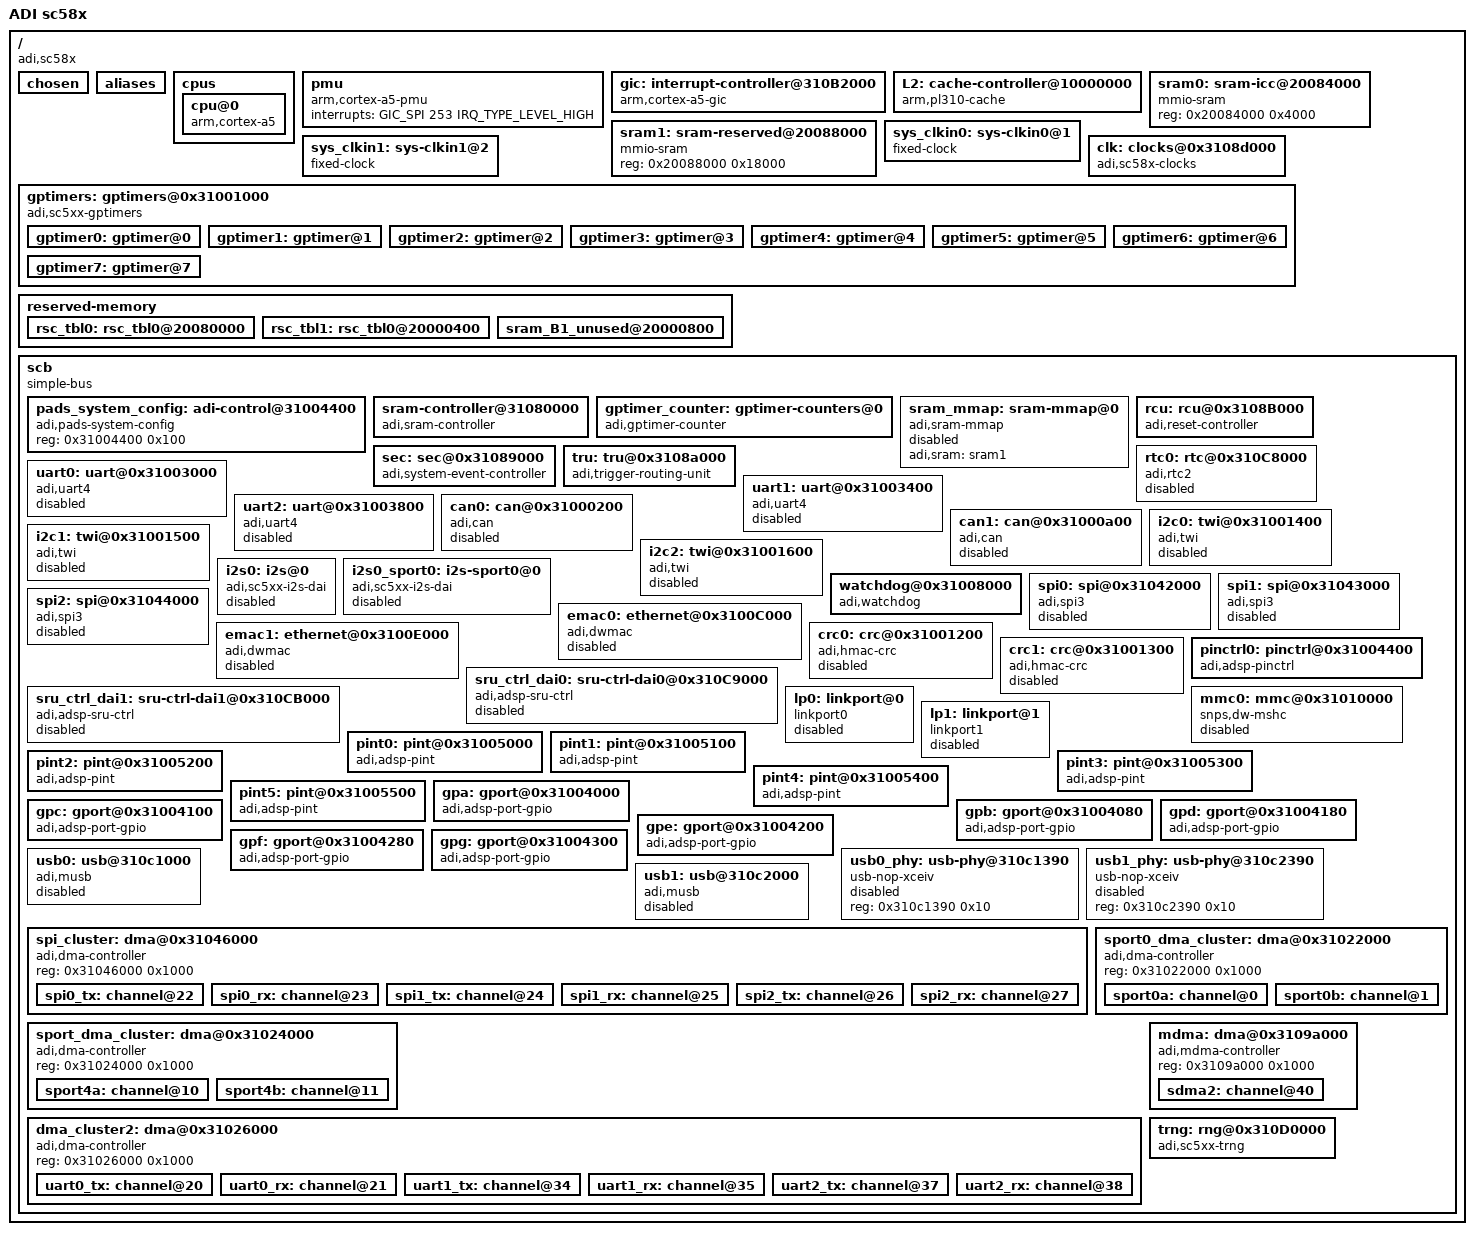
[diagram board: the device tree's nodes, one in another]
/*
 * Device tree header for ADI sc58x processor
 *
 * Copyright 2014 - 2018 Analog Devices Inc.
 *
 * Licensed under the GPL-2 or later.
 *
 */

#include <dt-bindings/interrupt-controller/arm-gic.h>
#include <dt-bindings/interrupt-controller/irq.h>
#include <dt-bindings/clock/adi-sc5xx-clock.h>

/ {
	model = "ADI sc58x";
	compatible = "adi,sc58x";
	interrupt-parent = <&gic>;
	#address-cells = <1>;
	#size-cells = <1>;

	chosen { };

	aliases {
		serial0 = &uart0;
		timer0 = &gptimer0;
		timer1 = &gptimer1;
		timer2 = &gptimer2;
		timer3 = &gptimer3;
		timer4 = &gptimer4;
		timer5 = &gptimer5;
		timer6 = &gptimer6;
		timer7 = &gptimer7;
		ethernet0 = &emac0;
		ethernet1 = &emac1;
		spi0   = &spi0;
		spi1   = &spi1;
		spi2   = &spi2;
		can0 = &can0;
		can1 = &can1;
		i2c0 = &i2c0;
		i2c1 = &i2c1;
		i2c2 = &i2c2;
		rtc0 = &rtc0;
		i2s0 = &i2s0;
		mmc0 = &mmc0;
		sru0 = &sru_ctrl_dai0;
		sru1 = &sru_ctrl_dai1;
	};

	cpus {
		#size-cells = <0>;
		#address-cells = <1>;

		cpu@0 {
			device_type = "cpu";
			compatible = "arm,cortex-a5";
			reg = <0x0>;
			clocks = <&clk ADSP_SC58X_CLK_ARM>;
		};
	};

	pmu {
		compatible = "arm,cortex-a5-pmu";
		interrupts = <GIC_SPI 253 IRQ_TYPE_LEVEL_HIGH>;
	};

	gic: interrupt-controller@310B2000 {
		compatible = "arm,cortex-a5-gic", "arm,cortex-a9-gic";
		#interrupt-cells = <3>;
		#address-cells = <0>;
		interrupt-controller;
		reg = <0x310B2000 0x1000>,
		      <0x310B4000 0x100>;
	};

	L2: cache-controller@10000000 {
		compatible = "arm,pl310-cache";
		reg = <0x10000000 0x1000>;
		cache-level = <2>;
	};

	sram0: sram-icc@20084000 {
		compatible = "mmio-sram";
		#address-cells = <1>;
		#size-cells = <1>;
		reg = <0x20084000 0x4000>;
		ranges = <0 0x20084000 0x4000>; /* 16 KiB */
	};

	sram1: sram-reserved@20088000 {
		compatible = "mmio-sram";
		#address-cells = <1>;
		#size-cells = <1>;
		reg = <0x20088000 0x18000>;
		ranges = <0 0x20088000 0x18000>; /* 96 KiB */
	};

	sys_clkin0: sys-clkin0@1 {
		compatible = "fixed-clock";
		#clock-cells = <0>;
		clock-frequency = <25000000>;
		clock-output-names = "sys_clkin0";
	};

	sys_clkin1: sys-clkin1@2 {
		compatible = "fixed-clock";
		#clock-cells = <0>;
		clock-frequency = <25000000>;
		clock-output-names = "sys_clkin1";
	};

	clk: clocks@0x3108d000 {
		compatible = "adi,sc58x-clocks";
		reg = <0x3108d000 0x1000>,
			<0x3108e000 0x1000>,
			<0x3108f000 0x1000>;
		#clock-cells = <1>;
		clocks = <&sys_clkin0>, <&sys_clkin1>;
		clock-names = "sys_clkin0", "sys_clkin1";
		status = "okay";
	};

	gptimers: gptimers@0x31001000 {
		compatible = "adi,sc5xx-gptimers";
		reg = <0x31001000 0x200>;
		clocks = <&clk ADSP_SC58X_CLK_CGU0_SCLK0>;
		status = "okay";
		#address-cells = <1>;
		#size-cells = <0>;

		gptimer0: gptimer@0 {
			reg = <0>;
			interrupt-parent = <&gic>;
			interrupts = <GIC_SPI 26 IRQ_TYPE_LEVEL_HIGH>;
			adi,offset = <0x60>;
			adi,is-clocksource;
			adi,reset-timer;
		};

		gptimer1: gptimer@1 {
			reg = <1>;
			interrupt-parent = <&gic>;
			interrupts = <GIC_SPI 27 IRQ_TYPE_LEVEL_HIGH>;
			adi,offset = <0x80>;
			adi,is-clockevent;
			adi,reset-timer;
		};

		gptimer2: gptimer@2 {
			reg = <2>;
			interrupt-parent = <&gic>;
			interrupts = <GIC_SPI 28 IRQ_TYPE_LEVEL_HIGH>;
			adi,offset = <0xa0>;
		};

		gptimer3: gptimer@3 {
			reg = <3>;
			interrupt-parent = <&gic>;
			interrupts = <GIC_SPI 29 IRQ_TYPE_LEVEL_HIGH>;
			adi,offset = <0xc0>;
		};

		gptimer4: gptimer@4 {
			reg = <4>;
			interrupt-parent = <&gic>;
			interrupts = <GIC_SPI 72 IRQ_TYPE_LEVEL_HIGH>;
			adi,offset = <0xe0>;
		};

		gptimer5: gptimer@5 {
			reg = <5>;
			interrupt-parent = <&gic>;
			interrupts = <GIC_SPI 73 IRQ_TYPE_LEVEL_HIGH>;
			adi,offset = <0x100>;
		};

		gptimer6: gptimer@6 {
			reg = <6>;
			interrupt-parent = <&gic>;
			interrupts = <GIC_SPI 74 IRQ_TYPE_LEVEL_HIGH>;
			adi,offset = <0x120>;
		};

		gptimer7: gptimer@7 {
			reg = <7>;
			interrupt-parent = <&gic>;
			interrupts = <GIC_SPI 75 IRQ_TYPE_LEVEL_HIGH>;
			adi,offset = <0x140>;
		};
	};

	reserved-memory {
		#address-cells = <1>;
		#size-cells = <1>;
		ranges;

		rsc_tbl0: rsc_tbl0@20080000 {
			reg = <0x20080000 0x400>; /*1KiB*/
			no-map;
		};

		rsc_tbl1: rsc_tbl0@20000400 {
			reg = <0x20080400 0x400>; /*1KiB*/
			no-map;
		};

		sram_B1_unused@20000800 {
			reg = <0x20080800 0x3800>; /* <128 KiB*/
			no-map;
		};
	};

	scb {
		compatible = "simple-bus";
		#address-cells = <1>;
		#size-cells = <1>;
		ranges;

		pads_system_config: adi-control@31004400 {
			compatible = "adi,pads-system-config";
			reg = <0x31004400 0x100>;
			status = "okay";
		};

		sram-controller@31080000 {
			compatible = "adi,sram-controller";
			reg = <0x31080000 0x100>;
			adi,sram = <&sram0>, <&sram1>;
			interrupts = <GIC_SPI 10 IRQ_TYPE_LEVEL_HIGH>;
			status = "okay";
		};

		gptimer_counter: gptimer-counters@0 {
			compatible = "adi,gptimer-counter";
			status = "okay";
		};

		sram_mmap: sram-mmap@0 { /* mmap from sram1 pool*/
			compatible = "adi,sram-mmap";
			adi,sram = <&sram1>;
			status = "disabled";
		};

		rcu: rcu@0x3108B000 {
			compatible = "adi,reset-controller";
			reg = <0x3108B000 0x1000>;
			adi,sharc-min = <1>;
			adi,sharc-max = <2>;
			adi,enable-reboot;
			status = "okay";
		};

		sec: sec@0x31089000 {
			compatible = "adi,system-event-controller";
			reg = <0x31089000 0x1000>;
			adi,rcu = <&rcu>;
			adi,sharc-cores = <2>;
			status = "okay";
		};

		tru: tru@0x3108a000 {
			compatible = "adi,trigger-routing-unit";
			reg = <0x3108a000 0x1000>;
			adi,max-master-id = <139>;
			adi,max-slave-id = <137>;
			status = "okay";
		};

		rtc0: rtc@0x310C8000 {
			compatible = "adi,rtc2";
			reg = <0x310C8000 0x100>;
			interrupts = <GIC_SPI 165 IRQ_TYPE_LEVEL_HIGH>;
			calibration = /bits/ 8 <0>;
			status = "disabled";
		};

		uart0: uart@0x31003000 {
			compatible = "adi,uart4";
			reg = <0x31003000 0x40>;
			dmas = <&dma_cluster2 20>, <&dma_cluster2 21>;
			dma-names = "tx", "rx";
			interrupt-parent = <&gic>;
			interrupt-names = "tx", "rx", "status";
			interrupts = <GIC_SPI 114 IRQ_TYPE_LEVEL_HIGH>,
				     <GIC_SPI 115 IRQ_TYPE_LEVEL_HIGH>,
				     <GIC_SPI 116 IRQ_TYPE_LEVEL_HIGH>;
			clocks = <&clk ADSP_SC58X_CLK_CGU0_SCLK0>;
			clock-names = "sclk0";
			status = "disabled";
		};

		uart1: uart@0x31003400 {
			compatible = "adi,uart4";
			reg = <0x31003400 0x40>;
			dmas = <&dma_cluster2 34>, <&dma_cluster2 35>;
			dma-names = "tx", "rx";
			interrupt-parent = <&gic>;
			interrupt-names = "tx", "rx", "status";
			interrupts = <GIC_SPI 117 IRQ_TYPE_LEVEL_HIGH>,
				     <GIC_SPI 118 IRQ_TYPE_LEVEL_HIGH>,
				     <GIC_SPI 119 IRQ_TYPE_LEVEL_HIGH>;
			clocks = <&clk ADSP_SC58X_CLK_CGU0_SCLK0>;
			clock-names = "sclk0";
			status = "disabled";
		};

		uart2: uart@0x31003800 {
			compatible = "adi,uart4";
			reg = <0x31003800 0x40>;
			dmas = <&dma_cluster2 37>, <&dma_cluster2 38>;
			dma-names = "tx", "rx";
			interrupt-parent = <&gic>;
			interrupt-names = "tx", "rx", "status";
			interrupts = <GIC_SPI 120 IRQ_TYPE_LEVEL_HIGH>,
				     <GIC_SPI 121 IRQ_TYPE_LEVEL_HIGH>,
				     <GIC_SPI 122 IRQ_TYPE_LEVEL_HIGH>;
			clocks = <&clk ADSP_SC58X_CLK_CGU0_SCLK0>;
			clock-names = "sclk0";
			status = "disabled";
		};

		can0: can@0x31000200 {
			compatible = "adi,can";
			reg = <0x31000200 0x5FF>;
			interrupt-parent = <&gic>;
			interrupts = <GIC_SPI 84 IRQ_TYPE_LEVEL_HIGH>,
				     <GIC_SPI 85 IRQ_TYPE_LEVEL_HIGH>,
				     <GIC_SPI 86 IRQ_TYPE_LEVEL_HIGH>;
			status = "disabled";
		};

		can1: can@0x31000a00 {
			compatible = "adi,can";
			reg = <0x31000a00 0x5FF>;
			interrupt-parent = <&gic>;
			interrupts = <GIC_SPI 87 IRQ_TYPE_LEVEL_HIGH>,
				     <GIC_SPI 88 IRQ_TYPE_LEVEL_HIGH>,
				     <GIC_SPI 89 IRQ_TYPE_LEVEL_HIGH>;
			status = "disabled";
		};

		i2c0: twi@0x31001400 {
			#address-cells = <1>;
			#size-cells = <0>;
			compatible = "adi,twi";
			reg = <0x31001400 0xFF>;
			interrupts = <GIC_SPI 123 IRQ_TYPE_LEVEL_HIGH>;
			clock-khz = <100>;
			clocks = <&clk ADSP_SC58X_CLK_CGU0_SCLK0>;
			clock-names = "sclk0";
			status = "disabled";
		};

		i2c1: twi@0x31001500 {
			#address-cells = <1>;
			#size-cells = <0>;
			compatible = "adi,twi";
			reg = <0x31001500 0xFF>;
			interrupts = <GIC_SPI 124 IRQ_TYPE_LEVEL_HIGH>;
			clock-khz = <100>;
			clocks = <&clk ADSP_SC58X_CLK_CGU0_SCLK0>;
			clock-names = "sclk0";
			status = "disabled";
		};

		i2c2: twi@0x31001600 {
			#address-cells = <1>;
			#size-cells = <0>;
			compatible = "adi,twi";
			reg = <0x31001600 0xFF>;
			interrupts = <GIC_SPI 125 IRQ_TYPE_LEVEL_HIGH>;
			clock-khz = <100>;
			clocks = <&clk ADSP_SC58X_CLK_CGU0_SCLK0>;
			clock-names = "sclk0";
			status = "disabled";
		};

		i2s0: i2s@0 {
			compatible = "adi,sc5xx-i2s-dai";
			reg = <0x31002400 0x80>, <0x31002480 0x80>;
			sport-channel = <4>;
			interrupt-names = "tx_status", "rx_status";
			interrupts = <GIC_SPI 61 IRQ_TYPE_LEVEL_HIGH>, <GIC_SPI 63 IRQ_TYPE_LEVEL_HIGH>;
			dmas = <&sport_dma_cluster 10>, <&sport_dma_cluster 11>;
			dma-names = "tx", "rx";
			iram = <&sram1>;
			clocks = <&clk ADSP_SC58X_CLK_CGU0_SCLK1>;
			clock-names = "sclk";
			status = "disabled";
		};

		i2s0_sport0: i2s-sport0@0 {
			compatible = "adi,sc5xx-i2s-dai";
			reg = <0x31002000 0x80>, <0x31002080 0x80>;
			sport-channel = <0>;
			interrupt-names = "tx_status", "rx_status";
			interrupts = <GIC_SPI 53 IRQ_TYPE_LEVEL_HIGH>, <GIC_SPI 55 IRQ_TYPE_LEVEL_HIGH>;
			dmas = <&sport0_dma_cluster 0>, <&sport0_dma_cluster 1>;
			dma-names = "tx", "rx";
			iram = <&sram1>;
			clocks = <&clk ADSP_SC58X_CLK_CGU0_SCLK1>;
			clock-names = "sclk";
			status = "disabled";
		};

		watchdog@0x31008000 {
			compatible = "adi,watchdog";
			reg = <0x31008000 0x10>;
			timeout-sec = <30>;
			clocks = <&clk ADSP_SC58X_CLK_CGU0_SCLK0>;
			clock-names = "adi-watchdog";
		};

		spi0: spi@0x31042000 {
			#address-cells = <1>;
			#size-cells = <0>;
			compatible = "adi,spi3";
			reg = <0x31042000 0xFF>;
			interrupts = <GIC_SPI 109 IRQ_TYPE_LEVEL_HIGH>;
			dmas = <&spi_cluster 22>, <&spi_cluster 23>;
			dma-names = "tx", "rx";
			clocks = <&clk ADSP_SC58X_CLK_CGU0_SCLK1>;
			clock-names = "spi";
			status = "disabled";
		};

		spi1: spi@0x31043000 {
			#address-cells = <1>;
			#size-cells = <0>;
			compatible = "adi,spi3";
			reg = <0x31043000 0xFF>;
			interrupts = <GIC_SPI 113 IRQ_TYPE_LEVEL_HIGH>;
			dmas = <&spi_cluster 24>, <&spi_cluster 25>;
			dma-names = "tx", "rx";
			clocks = <&clk ADSP_SC58X_CLK_CGU0_SCLK0>;
			clock-names = "spi";
			status = "disabled";
		};

		spi2: spi@0x31044000 {
			#address-cells = <1>;
			#size-cells = <0>;
			compatible = "adi,spi3";
			reg = <0x31044000 0xFF>;
			interrupts = <GIC_SPI 71 IRQ_TYPE_LEVEL_HIGH>;
			dmas = <&spi_cluster 26>, <&spi_cluster 27>;
			dma-names = "tx", "rx";
			clocks = <&clk ADSP_SC58X_CLK_CGU0_SCLK0>;
			clock-names = "spi";
			status = "disabled";
		};

		emac0: ethernet@0x3100C000 {
			compatible = "adi,dwmac", "snps,dwmac-3.710", "snps,dwmac";
			reg = <0x3100C000 0x2000>;
			interrupt-parent = <&gic>;
			interrupts = <GIC_SPI 148 IRQ_TYPE_LEVEL_HIGH>;
			interrupt-names = "macirq";
			snps,mixed-burst;
			snps,pbl = <8>;
			snps,force_sf_dma_mode;
			snps,perfect-filter-entries = <32>;
			clocks = <&clk ADSP_SC58X_CLK_GIGE>;
			clock-names = "stmmaceth";
			adi,system-config = <&pads_system_config>;
			status = "disabled";
		};

		emac1: ethernet@0x3100E000 {
			compatible = "adi,dwmac", "snps,dwmac-3.710", "snps,dwmac";
			reg = <0x3100E000 0x2000>;
			interrupt-parent = <&gic>;
			interrupts = <GIC_SPI 149 IRQ_TYPE_LEVEL_HIGH>;
			interrupt-names = "macirq";
			snps,fixed-burst;
			snps,burst_len = <0x4>;	/* BLEN8 */
			snps,pbl = <1>;
			snps,force_thresh_dma_mode;
			clocks = <&clk ADSP_SC58X_CLK_GIGE>;
			clock-names = "stmmaceth";
			status = "disabled";
		};

		crc0: crc@0x31001200 {
			compatible = "adi,hmac-crc";
			reg = <0x31001200 0xFF>;
			interrupts = <GIC_SPI 176 IRQ_TYPE_LEVEL_HIGH>;
			dma_channel = <8>;
			crypto_crc_poly = <0x5c5c5c5c>;
			status = "disabled";
		};

		crc1: crc@0x31001300 {
			compatible = "adi,hmac-crc";
			reg = <0x31001300 0xFF>;
			interrupts = <GIC_SPI 177 IRQ_TYPE_LEVEL_HIGH>;
			dma_channel = <18>;
			crypto_crc_poly = <0x5c5c5c5c>;
			status = "disabled";
		};

		pinctrl0: pinctrl@0x31004400 {
			compatible = "adi,adsp-pinctrl";
			#address-cells = <1>;
			#size-cells = <1>;
			reg = <0x31004400 0x400>;
			adi,port-sizes = <16 16 16 16 16 16 6>;
			adi,no-drive-strength;
			adi,no-pull-up-down;
		};

		sru_ctrl_dai0: sru-ctrl-dai0@0x310C9000 {
			compatible = "adi,adsp-sru-ctrl";
			#address-cells = <1>;
			#size-cells = <1>;
			reg = <0x310C9000 0x224>;
			adi,system-config = <&pads_system_config>;
			status = "disabled";
		};

		sru_ctrl_dai1: sru-ctrl-dai1@0x310CB000 {
			compatible = "adi,adsp-sru-ctrl";
			#address-cells = <1>;
			#size-cells = <1>;
			reg = <0x310CB000 0x224>;
			adi,system-config = <&pads_system_config>;
			status = "disabled";
		};

		mmc0: mmc@0x31010000 {
			compatible = "snps,dw-mshc";
			reg = <0x31010000 0xFFF>;
			interrupts = <GIC_SPI 131 IRQ_TYPE_LEVEL_HIGH>;
			#address-cells = <1>;
			#size-cells = <0>;
			fifo-depth = <1024>;
			clocks = <&clk ADSP_SC58X_CLK_SDIO>,
					<&clk ADSP_SC58X_CLK_CGU0_SCLK0>;
			clock-names = "ciu", "biu";
			status = "disabled";
		};

		lp0: linkport@0 {
			compatible = "linkport0";
			interrupt-parent = <&gic>;
			interrupts = <GIC_SPI 77 IRQ_TYPE_LEVEL_HIGH>,
				     <GIC_SPI 78 IRQ_TYPE_LEVEL_HIGH>;
			clock-div = <1>;
			status = "disabled";
		};

		lp1: linkport@1 {
			compatible = "linkport1";
			interrupt-parent = <&gic>;
			interrupts = <GIC_SPI 79 IRQ_TYPE_LEVEL_HIGH>,
				     <GIC_SPI 80 IRQ_TYPE_LEVEL_HIGH>;
			clock-div = <1>;
			status = "disabled";
		};

		pint0: pint@0x31005000 {
			compatible = "adi,adsp-pint";
			reg = <0x31005000 0xFF>;
			interrupts = <GIC_SPI 38 IRQ_TYPE_LEVEL_HIGH>;
		};

		pint1: pint@0x31005100 {
			compatible = "adi,adsp-pint";
			reg = <0x31005100 0xFF>;
			interrupts = <GIC_SPI 39 IRQ_TYPE_LEVEL_HIGH>;
		};

		pint2: pint@0x31005200 {
			compatible = "adi,adsp-pint";
			reg = <0x31005200 0xFF>;
			interrupts = <GIC_SPI 40 IRQ_TYPE_LEVEL_HIGH>;
		};

		pint3: pint@0x31005300 {
			compatible = "adi,adsp-pint";
			reg = <0x31005300 0xFF>;
			interrupts = <GIC_SPI 41 IRQ_TYPE_LEVEL_HIGH>;
		};

		pint4: pint@0x31005400 {
			compatible = "adi,adsp-pint";
			reg = <0x31005400 0xFF>;
			interrupts = <GIC_SPI 42 IRQ_TYPE_LEVEL_HIGH>;
		};

		pint5: pint@0x31005500 {
			compatible = "adi,adsp-pint";
			reg = <0x31005500 0xFF>;
			interrupts = <GIC_SPI 43 IRQ_TYPE_LEVEL_HIGH>;
		};

		gpa: gport@0x31004000 {
			compatible = "adi,adsp-port-gpio";
			gpio-controller;
			#gpio-cells = <2>;
			reg = <0x31004000 0x7F>;
			gpio-ranges = <&pinctrl0 0 0 16>;
			adi,pint = <&pint0 1>;
			adi,gpio-base = <0>;
		};

		gpb: gport@0x31004080 {
			compatible = "adi,adsp-port-gpio";
			gpio-controller;
			#gpio-cells = <2>;
			reg = <0x31004080 0x7F>;
			gpio-ranges = <&pinctrl0 0 16 16>;
			adi,pint = <&pint0 0>;
			adi,gpio-base = <16>;
		};

		gpc: gport@0x31004100 {
			compatible = "adi,adsp-port-gpio";
			gpio-controller;
			#gpio-cells = <2>;
			reg = <0x31004100 0x7F>;
			gpio-ranges = <&pinctrl0 0 32 16>;
			adi,pint = <&pint2 1>;
			adi,gpio-base = <32>;
		};

		gpd: gport@0x31004180 {
			compatible = "adi,adsp-port-gpio";
			gpio-controller;
			#gpio-cells = <2>;
			reg = <0x31004180 0x7F>;
			gpio-ranges = <&pinctrl0 0 48 16>;
			adi,pint = <&pint2 0>;
			adi,gpio-base = <48>;
		};

		gpe: gport@0x31004200 {
			compatible = "adi,adsp-port-gpio";
			gpio-controller;
			#gpio-cells = <2>;
			reg = <0x31004200 0x7F>;
			gpio-ranges = <&pinctrl0 0 64 16>;
			adi,pint = <&pint4 1>;
			adi,gpio-base = <64>;
		};

		gpf: gport@0x31004280 {
			compatible = "adi,adsp-port-gpio";
			gpio-controller;
			#gpio-cells = <2>;
			reg = <0x31004280 0x7F>;
			gpio-ranges = <&pinctrl0 0 80 16>;
			adi,pint = <&pint4 0>;
			adi,gpio-base = <80>;
		};

		gpg: gport@0x31004300 {
			compatible = "adi,adsp-port-gpio";
			gpio-controller;
			#gpio-cells = <2>;
			reg = <0x31004300 0x7F>;
			gpio-ranges = <&pinctrl0 0 96 6>;
			adi,pint = <&pint5 0>;
			adi,gpio-base = <96>;
		};

		usb0_phy: usb-phy@310c1390 {
			compatible = "usb-nop-xceiv";
			reg = <0x310c1390 0x10>;
			reg-names = "phy";
			#phy-cells = <0>;
			status = "disabled";
		};

		usb0: usb@310c1000 {
			compatible = "adi,musb";
			reg = <0x310c1000 0x390>;
			reg-names = "mc";
			interrupts = <GIC_SPI 132 IRQ_TYPE_LEVEL_HIGH>,
					<GIC_SPI 133 IRQ_TYPE_LEVEL_HIGH>;
			interrupt-names = "mc", "dma";
			spu_securep_id = <153>;

			mentor,multipoint = <1>;
			mentor,num-eps = <16>;
			mentor,ram-bits = <12>;
			mentor,power = <500>;
			phys = <&usb0_phy>;
			status = "disabled";
		};

		usb1_phy: usb-phy@310c2390 {
			compatible = "usb-nop-xceiv";
			reg = <0x310c2390 0x10>;
			reg-names = "phy";
			#phy-cells = <0>;
			status = "disabled";
		};

		usb1: usb@310c2000 {
			compatible = "adi,musb";
			reg = <0x310c2000 0x390>;
			reg-names = "mc";
			interrupts = <GIC_SPI 134 IRQ_TYPE_LEVEL_HIGH>,
					<GIC_SPI 135 IRQ_TYPE_LEVEL_HIGH>;
			interrupt-names = "mc", "dma";
			spu_securep_id = <154>;

			mentor,multipoint = <1>;
			mentor,num-eps = <16>;
			mentor,ram-bits = <12>;
			mentor,power = <500>;
			phys = <&usb1_phy>;
			status = "disabled";
		};

/*
		dma0: dma@0 {
			compatible = "adi,dma2";
			reg = <0x31022000 0x7F>;
			interrupts = <GIC_SPI 52 IRQ_TYPE_LEVEL_HIGH>;
			spu_securep_id = <66>;
		};

		dma1: dma@1 {
			compatible = "adi,dma2";
			reg = <0x31022080 0x7F>;
			interrupts = <GIC_SPI 54 IRQ_TYPE_LEVEL_HIGH>;
			spu_securep_id = <67>;
		};

		dma2: dma@2 {
			compatible = "adi,dma2";
			reg = <0x31022100 0x7F>;
			interrupts = <GIC_SPI 56 IRQ_TYPE_LEVEL_HIGH>;
			spu_securep_id = <68>;
		};

		dma3: dma@3 {
			compatible = "adi,dma2";
			reg = <0x31022180 0x7F>;
			interrupts = <GIC_SPI 58 IRQ_TYPE_LEVEL_HIGH>;
			spu_securep_id = <69>;
		};

		dma4: dma@4 {
			compatible = "adi,dma2";
			reg = <0x31022200 0x7F>;
			interrupts = <GIC_SPI 90 IRQ_TYPE_LEVEL_HIGH>;
			spu_securep_id = <70>;
		};

		dma5: dma@5 {
			compatible = "adi,dma2";
			reg = <0x31022280 0x7F>;
			interrupts = <GIC_SPI 92 IRQ_TYPE_LEVEL_HIGH>;
			spu_securep_id = <71>;
		};

		dma6: dma@6 {
			compatible = "adi,dma2";
			reg = <0x31022300 0x7F>;
			interrupts = <GIC_SPI 94 IRQ_TYPE_LEVEL_HIGH>;
			spu_securep_id = <72>;
		};

		dma7: dma@7 {
			compatible = "adi,dma2";
			reg = <0x31022380 0x7F>;
			interrupts = <GIC_SPI 96 IRQ_TYPE_LEVEL_HIGH>;
			spu_securep_id = <73>;
		};

		dma8: dma@8 {
			compatible = "adi,dma2";
			reg = <0x31028000 0x7F>;
			interrupts = <GIC_SPI 172 IRQ_TYPE_LEVEL_HIGH>;
			spu_securep_id = <88>;
		};

		dma9: dma@9 {
			compatible = "adi,dma2";
			reg = <0x31028080 0x7F>;
			interrupts = <GIC_SPI 173 IRQ_TYPE_LEVEL_HIGH>;
			spu_securep_id = <89>;
		};

		dma10: dma@10 {
			compatible = "adi,dma2";
			reg = <0x31024000 0x7F>;
			interrupts = <GIC_SPI 60 IRQ_TYPE_LEVEL_HIGH>;
			spu_securep_id = <74>;
		};

		dma11: dma@11 {
			compatible = "adi,dma2";
			reg = <0x31024080 0x7F>;
			interrupts = <GIC_SPI 62 IRQ_TYPE_LEVEL_HIGH>;
			spu_securep_id = <75>;
		};

		dma12: dma@012 {
			compatible = "adi,dma2";
			reg = <0x31024100 0x7F>;
			interrupts = <GIC_SPI 64 IRQ_TYPE_LEVEL_HIGH>;
			spu_securep_id = <76>;
		};

		dma13: dma@13 {
			compatible = "adi,dma2";
			reg = <0x31024180 0x7F>;
			interrupts = <GIC_SPI 66 IRQ_TYPE_LEVEL_HIGH>;
			spu_securep_id = <77>;
		};

		dma14: dma@14 {
			compatible = "adi,dma2";
			reg = <0x31024200 0x7F>;
			interrupts = <GIC_SPI 98 IRQ_TYPE_LEVEL_HIGH>;
			spu_securep_id = <78>;
		};

		dma15: dma@15 {
			compatible = "adi,dma2";
			reg = <0x31024280 0x7F>;
			interrupts = <GIC_SPI 100 IRQ_TYPE_LEVEL_HIGH>;
			spu_securep_id = <79>;
		};

		dma16: dma@16 {
			compatible = "adi,dma2";
			reg = <0x31024300 0x7F>;
			interrupts = <GIC_SPI 102 IRQ_TYPE_LEVEL_HIGH>;
			spu_securep_id = <80>;
		};

		dma17: dma@17 {
			compatible = "adi,dma2";
			reg = <0x31024380 0x7F>;
			interrupts = <GIC_SPI 104 IRQ_TYPE_LEVEL_HIGH>;
			spu_securep_id = <81>;
		};

		dma18: dma@18 {
			compatible = "adi,dma2";
			reg = <0x31028100 0x7F>;
			interrupts = <GIC_SPI 174 IRQ_TYPE_LEVEL_HIGH>;
			spu_securep_id = <90>;
		};

		dma19: dma@19 {
			compatible = "adi,dma2";
			reg = <0x31028180 0x7F>;
			interrupts = <GIC_SPI 175 IRQ_TYPE_LEVEL_HIGH>;
			spu_securep_id = <91>;
		};

		dma20: dma@20 {
			compatible = "adi,dma2";
			reg = <0x31026080 0x7F>;
			interrupts = <GIC_SPI 114 IRQ_TYPE_LEVEL_HIGH>;
			spu_securep_id = <83>;
		};

		dma21: dma@21 {
			compatible = "adi,dma2";
			reg = <0x31026000 0x7F>;
			interrupts = <GIC_SPI 115 IRQ_TYPE_LEVEL_HIGH>;
			spu_securep_id = <82>;
		};

		dma22: dma@22 {
			compatible = "adi,dma2";
			reg = <0x31046000 0x7F>;
			interrupts = <GIC_SPI 106 IRQ_TYPE_LEVEL_HIGH>;
			spu_securep_id = <101>;
		};

		dma23: dma@23 {
			compatible = "adi,dma2";
			reg = <0x31046080 0x7F>;
			interrupts = <GIC_SPI 107 IRQ_TYPE_LEVEL_HIGH>;
			spu_securep_id = <102>;
		};

		dma24: dma@24 {
			compatible = "adi,dma2";
			reg = <0x31046100 0x7F>;
			interrupts = <GIC_SPI 110 IRQ_TYPE_LEVEL_HIGH>;
			spu_securep_id = <103>;
		};

		dma25: dma@25 {
			compatible = "adi,dma2";
			reg = <0x31046180 0x7F>;
			interrupts = <GIC_SPI 111 IRQ_TYPE_LEVEL_HIGH>;
			spu_securep_id = <104>;
		};

		dma26: dma@26 {
			compatible = "adi,dma2";
			reg = <0x31046200 0x7F>;
			interrupts = <GIC_SPI 68 IRQ_TYPE_LEVEL_HIGH>;
			spu_securep_id = <105>;
		};

		dma27: dma@27 {
			compatible = "adi,dma2";
			reg = <0x31046280 0x7F>;
			interrupts = <GIC_SPI 69 IRQ_TYPE_LEVEL_HIGH>;
			spu_securep_id = <106>;
		};

		dma28: dma@28 {
			compatible = "adi,dma2";
			reg = <0x31046300 0x7F>;
			interrupts = <GIC_SPI 81 IRQ_TYPE_LEVEL_HIGH>;
			spu_securep_id = <107>;
		};

		dma29: dma@29 {
			compatible = "adi,dma2";
			reg = <0x31046380 0x7F>;
			interrupts = <GIC_SPI 82 IRQ_TYPE_LEVEL_HIGH>;
			spu_securep_id = <108>;
		};

		dma30: dma@30 {
			compatible = "adi,dma2";
			reg = <0x30FFF000 0x7F>;
			interrupts = <GIC_SPI 77 IRQ_TYPE_LEVEL_HIGH>;
			spu_securep_id = <5>;
		};

		dma31: dma@31 {
			compatible = "adi,dma2";
			reg = <0x3102A100 0x7F>;
			interrupts = <GIC_SPI 160 IRQ_TYPE_LEVEL_HIGH>;
			spu_securep_id = <94>;
		};

		dma32: dma@32 {
			compatible = "adi,dma2";
			reg = <0x3102A000 0x7F>;
			interrupts = <GIC_SPI 158 IRQ_TYPE_LEVEL_HIGH>;
			spu_securep_id = <92>;
		};

		dma33: dma@33 {
			compatible = "adi,dma2";
			reg = <0x3102A080 0x7F>;
			interrupts = <GIC_SPI 159 IRQ_TYPE_LEVEL_HIGH>;
			spu_securep_id = <93>;
		};

		dma34: dma@34 {
			compatible = "adi,dma2";
			reg = <0x31026180 0x7F>;
			interrupts = <GIC_SPI 117 IRQ_TYPE_LEVEL_HIGH>;
			spu_securep_id = <85>;
		};

		dma35: dma@35 {
			compatible = "adi,dma2";
			reg = <0x31026100 0x7F>;
			interrupts = <GIC_SPI 118 IRQ_TYPE_LEVEL_HIGH>;
			spu_securep_id = <84>;
		};

		dma36: dma@36 {
			compatible = "adi,dma2";
			reg = <0x30FFF080 0x7F>;
			interrupts = <GIC_SPI 79 IRQ_TYPE_LEVEL_HIGH>;
			spu_securep_id = <6>;
		};

		dma37: dma@37 {
			compatible = "adi,dma2";
			reg = <0x31026280 0x7F>;
			interrupts = <GIC_SPI 120 IRQ_TYPE_LEVEL_HIGH>;
			spu_securep_id = <87>;
		};

		dma38: dma@38 {
			compatible = "adi,dma2";
			reg = <0x31026200 0x7F>;
			interrupts = <GIC_SPI 121 IRQ_TYPE_LEVEL_HIGH>;
			spu_securep_id = <86>;
		};

		dma39: dma@39 {
			compatible = "adi,dma2";
			reg = <0x3109A000 0x7F>;
			interrupts = <GIC_SPI 168 IRQ_TYPE_LEVEL_HIGH>;
			spu_securep_id = <140>;
		};

		dma40: dma@40 {
			compatible = "adi,dma2";
			reg = <0x3109A080 0x7F>;
			interrupts = <GIC_SPI 169 IRQ_TYPE_LEVEL_HIGH>;
			spu_securep_id = <140>;
		};

		dma41: dma@41 {
			compatible = "adi,dma2";
			reg = <0x3109C200 0x7F>;
			interrupts = <GIC_SPI 151 IRQ_TYPE_LEVEL_HIGH>;
			spu_securep_id = <142>;
		};

		dma42: dma@42 {
			compatible = "adi,dma2";
			reg = <0x3109C400 0x7F>;
			interrupts = <GIC_SPI 150 IRQ_TYPE_LEVEL_HIGH>;
			spu_securep_id = <142>;
		};

		dma43: dma@43 {
			compatible = "adi,dma2";
			reg = <0x3109B000 0x7F>;
			interrupts = <GIC_SPI 166 IRQ_TYPE_LEVEL_HIGH>;
			spu_securep_id = <141>;
		};

		dma44: dma@44 {
			compatible = "adi,dma2";
			reg = <0x3109B080 0x7F>;
			interrupts = <GIC_SPI 167 IRQ_TYPE_LEVEL_HIGH>;
			spu_securep_id = <141>;
		};
*/

		spi_cluster: dma@0x31046000 {
			compatible = "adi,dma-controller";
			reg = <0x31046000 0x1000>;
			status = "okay";
			#dma-cells = <1>;

			spi0_tx: channel@22 {
				adi,id = <22>;
				interrupts = <GIC_SPI 106 IRQ_TYPE_LEVEL_HIGH>,
					<GIC_SPI 198 IRQ_TYPE_LEVEL_HIGH>;
				interrupt-names = "complete", "error";
				adi,src-offset = <0>;
			};

			spi0_rx: channel@23 {
				adi,id = <23>;
				interrupts = <GIC_SPI 107 IRQ_TYPE_LEVEL_HIGH>,
					<GIC_SPI 199 IRQ_TYPE_LEVEL_HIGH>;
				interrupt-names = "complete", "error";
				adi,src-offset = <0x80>;
			};

			spi1_tx: channel@24 {
				adi,id = <24>;
				interrupts = <GIC_SPI 110 IRQ_TYPE_LEVEL_HIGH>,
					<GIC_SPI 200 IRQ_TYPE_LEVEL_HIGH>;
				interrupt-names = "complete", "error";
				adi,src-offset = <0x100>;
			};

			spi1_rx: channel@25 {
				adi,id = <25>;
				interrupts = <GIC_SPI 111 IRQ_TYPE_LEVEL_HIGH>,
					<GIC_SPI 201 IRQ_TYPE_LEVEL_HIGH>;
				interrupt-names = "complete", "error";
				adi,src-offset = <0x180>;
			};

			spi2_tx: channel@26 {
				adi,id = <26>;
				interrupts = <GIC_SPI 68 IRQ_TYPE_LEVEL_HIGH>,
					<GIC_SPI 188 IRQ_TYPE_LEVEL_HIGH>;
				interrupt-names = "complete", "error";
				adi,src-offset = <0x200>;
			};

			spi2_rx: channel@27 {
				adi,id = <27>;
				interrupts = <GIC_SPI 69 IRQ_TYPE_LEVEL_HIGH>,
					<GIC_SPI 189 IRQ_TYPE_LEVEL_HIGH>;
				interrupt-names = "complete", "error";
				adi,src-offset = <0x280>;
			};
		};

		sport_dma_cluster: dma@0x31024000 {
			compatible = "adi,dma-controller";
			reg = <0x31024000 0x1000>;
			status = "okay";
			#dma-cells = <1>;

			sport4a: channel@10 {
				adi,id = <10>;
				adi,src-offset = <0>;
				adi,skip-interrupts = <0>;
				interrupts = <GIC_SPI 60 IRQ_TYPE_LEVEL_HIGH>,
					<GIC_SPI 184 IRQ_TYPE_LEVEL_HIGH>;
				interrupt-names = "complete", "error";
			};

			sport4b: channel@11 {
				adi,id = <11>;
				adi,src-offset = <0x80>;
				adi,skip-interrupts = <0>;
				interrupts = <GIC_SPI 62 IRQ_TYPE_LEVEL_HIGH>,
					<GIC_SPI 185 IRQ_TYPE_LEVEL_HIGH>;
				interrupt-names = "complete", "error";
			};
		};

		sport0_dma_cluster: dma@0x31022000 {
			compatible = "adi,dma-controller";
			reg = <0x31022000 0x1000>;
			status = "okay";
			#dma-cells = <1>;

			sport0a: channel@0 {
				adi,id = <0>;
				adi,src-offset = <0>;
				adi,skip-interrupts = <0>;
				interrupts = <GIC_SPI 52 IRQ_TYPE_LEVEL_HIGH>,
					<GIC_SPI 180 IRQ_TYPE_LEVEL_HIGH>;
				interrupt-names = "complete", "error";
			};

			sport0b: channel@1 {
				adi,id = <1>;
				adi,src-offset = <0x80>;
				adi,skip-interrupts = <0>;
				interrupts = <GIC_SPI 54 IRQ_TYPE_LEVEL_HIGH>,
					<GIC_SPI 181 IRQ_TYPE_LEVEL_HIGH>;
				interrupt-names = "complete", "error";
			};
		};

		dma_cluster2: dma@0x31026000 {
			compatible = "adi,dma-controller";
			reg = <0x31026000 0x1000>;
			status = "okay";
			#dma-cells = <1>;

			uart0_tx: channel@20 {
				adi,id = <20>;
				interrupts = <GIC_SPI 114 IRQ_TYPE_LEVEL_HIGH>,
					<GIC_SPI 202 IRQ_TYPE_LEVEL_HIGH>;
				interrupt-names = "complete", "error";
				adi,src-offset = <0x80>;
			};

			uart0_rx: channel@21 {
				adi,id = <21>;
				interrupts = <GIC_SPI 115 IRQ_TYPE_LEVEL_HIGH>,
					<GIC_SPI 203 IRQ_TYPE_LEVEL_HIGH>;
				interrupt-names = "complete", "error";
				adi,src-offset = <0>;
			};

			uart1_tx: channel@34 {
				adi,id = <34>;
				interrupts = <GIC_SPI 117 IRQ_TYPE_LEVEL_HIGH>,
					<GIC_SPI 204 IRQ_TYPE_LEVEL_HIGH>;
				interrupt-names = "complete", "error";
				adi,src-offset = <0x180>;
			};

			uart1_rx: channel@35 {
				adi,id = <35>;
				interrupts = <GIC_SPI 118 IRQ_TYPE_LEVEL_HIGH>,
					<GIC_SPI 205 IRQ_TYPE_LEVEL_HIGH>;
				interrupt-names = "complete", "error";
				adi,src-offset = <0x100>;
			};

			uart2_tx: channel@37 {
				adi,id = <37>;
				interrupts = <GIC_SPI 120 IRQ_TYPE_LEVEL_HIGH>,
					<GIC_SPI 206 IRQ_TYPE_LEVEL_HIGH>;
				interrupt-names = "complete", "error";
				adi,src-offset = <0x280>;
			};

			uart2_rx: channel@38 {
				adi,id = <38>;
				interrupts = <GIC_SPI 121 IRQ_TYPE_LEVEL_HIGH>,
					<GIC_SPI 207 IRQ_TYPE_LEVEL_HIGH>;
				interrupt-names = "complete", "error";
				adi,src-offset = <0x200>;
			};
		};

		mdma: dma@0x3109a000 {
			compatible = "adi,mdma-controller";
			reg = <0x3109a000 0x1000>;
			status = "okay";

			sdma2: channel@40 {
				adi,id = <40>;
				// The destination interrupts are used for primary complete detection
				interrupts = <GIC_SPI 169 IRQ_TYPE_LEVEL_HIGH>,
					<GIC_SPI 222 IRQ_TYPE_LEVEL_HIGH>,
					<GIC_SPI 168 IRQ_TYPE_LEVEL_HIGH>,
					<GIC_SPI 221 IRQ_TYPE_LEVEL_HIGH>;
				interrupt-names = "complete", "error", "complete2", "error2";
				adi,src-offset = <0>;
				adi,dest-offset = <0x80>;
			};
		};

		trng: rng@0x310D0000 {
			compatible = "adi,sc5xx-trng";
			reg = <0x310D0000 0x74>, <0x310D8000 0x14>;
			interrupts = <GIC_SPI 129 IRQ_TYPE_LEVEL_HIGH>;
			interrupt-names = "pkic0_irq";
			startup-cycles = <0xff>;
			minref-cycles = <0x21>;
			maxref-cycles = <0x22>;
			alarm-thresh  = <0xff>;
			shdn-thresh = <0x04>;
			poll-data = <0>; /* Use IRQ for data */
			status = "okay";
		};

	};
};
